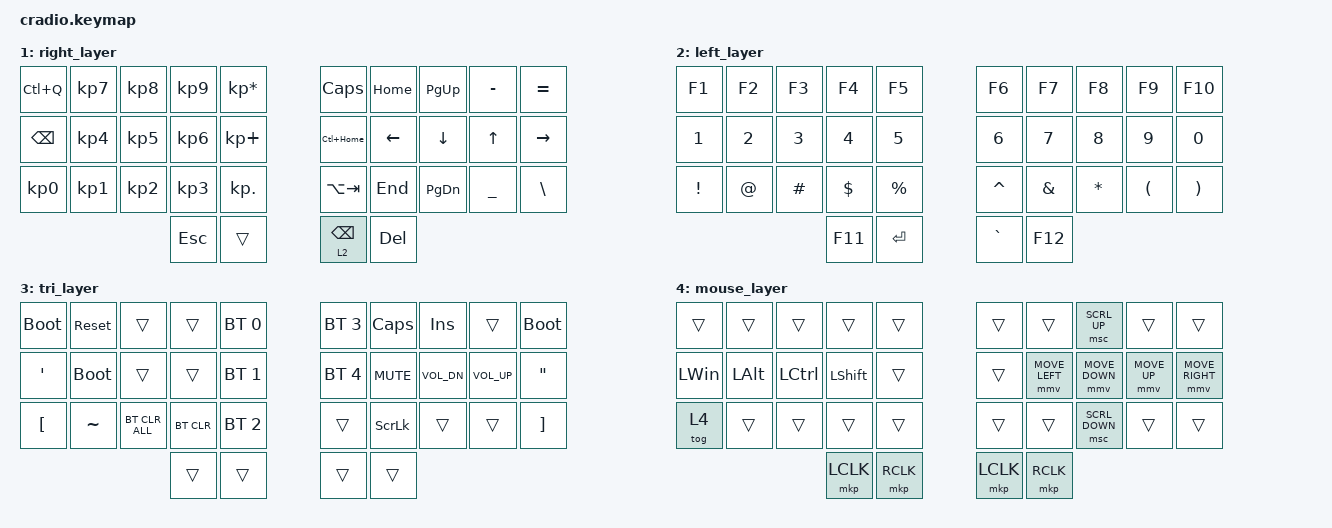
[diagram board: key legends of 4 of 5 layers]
// Copyright (c) 2022 The ZMK Contributors
// SPDX-License-Identifier: MIT

#include <behaviors.dtsi>
#include <dt-bindings/zmk/keys.h>
#include <dt-bindings/zmk/bt.h>

#define ZMK_POINTING_DEFAULT_MOVE_VAL 1500  // default: 600
#define ZMK_POINTING_DEFAULT_SCRL_VAL 20    // default: 10

#include <dt-bindings/zmk/pointing.h>

// Home row mods macro
#define HRML(k1,k2,k3,k4) &ht LGUI k1  &ht LALT k2  &ht LCTRL k3  &ht LSHFT k4
#define HRMR(k1,k2,k3,k4) &ht RSHFT k1  &ht RCTRL k2  &ht RALT k3  &ht RGUI k4

/ {
    behaviors {
        ht: hold_tap {
            label = "hold_tap";
            compatible = "zmk,behavior-hold-tap";
            #binding-cells = <2>;
            flavor = "tap-preferred";
            tapping-term-ms = <220>;
             quick-tap-ms = <150>;
            require-prior-idle-ms = <100>;
            bindings = <&kp>, <&kp>;
        };
    };
 
    combos {
        compatible = "zmk,combos";
        
        combo_esc {
            timeout-ms = <50>;
            key-positions = <0 1>;
            bindings = <&kp ESC>;
        };
        combo_singlequote {
            timeout-ms = <50>;
            key-positions = <18 19>;
            bindings = <&kp SINGLE_QUOTE>;
            layers = <0 1 2 3>;  // Disable in Mouse Layer
        };
        combo_return {
            timeout-ms = <50>;
            key-positions = <17 18>;
            bindings = <&kp ENTER>;
            layers = <0 1 2 3>;  // Disable in Mouse Layer
        };
         combo_doagain {
            timeout-ms = <50>;
            key-positions = <5 6>;
            bindings = <&kp LC(Y)>;
        };
        combo_dash {
            timeout-ms = <50>;
            key-positions = <6 7>;
            bindings = <&kp MINUS>;
        };
        combo_equal {
            timeout-ms = <25>;
            key-positions = <7 8>;
            bindings = <&kp EQUAL>;
            require-prior-idle-ms = <100>;
        };
         combo_backspace {
            timeout-ms = <50>;
            key-positions = <8 9>;
            bindings = <&kp BSPC>;
        };
         combo_bsword {
            timeout-ms = <50>;
            key-positions = <11 12>;
            bindings = <&kp LC(BSPC)>;
        };
          combo_undo {
            timeout-ms = <50>;
            key-positions = <20 21>;
            bindings = <&kp LC(Z)>;
        };
          combo_cut {
            timeout-ms = <50>;
            key-positions = <21 22>;
            bindings = <&kp LC(X)>;
        };
          combo_copy {
            timeout-ms = <50>;
            key-positions = <22 23>;
            bindings = <&kp LC(C)>;
        };
          combo_paste {
            timeout-ms = <50>;
            key-positions = <23 24>;
            bindings = <&kp LC(V)>;
        };
          combo_redo {
            timeout-ms = <50>;
            key-positions = <20 24>;
            bindings = <&kp LC(Y)>;
        };
        combo_togmouse {
            timeout-ms = <50>;
            key-positions = <10 31>;
            bindings = <&tog 4>;
        };
    };

    conditional_layers {
        compatible = "zmk,conditional-layers";
        tri_layer {
            if-layers = <1 2>;
            then-layer = <3>;
        };
    };


    keymap {
        compatible = "zmk,keymap";
        default_layer {
            bindings = <
        //╭──────────┬──────────┬──────────┬──────────┬──────────╮   ╭──────────┬──────────┬──────────┬──────────┬──────────╮
        //│  Q       │  W       │  E       │  R       │  T       │   │  Y       │  U       │  I       │  O       │  P       │
            &kp Q      &kp W      &kp E      &kp R      &kp T          &kp Y      &kp U      &kp I      &kp O      &kp P
        //├──────────┼──────────┼──────────┼──────────┼──────────┤   ├──────────┼──────────┼──────────┼──────────┼──────────┤
        //│  A       │  S       │  D       │  F       │  G       │   │  H       │  J       │  K       │  L       │ ; :      │
            HRML(A,        S,         D,         F)     &kp G          &kp H      HRMR(J,        K,         L,        SEMI)
        //├──────────┼──────────┼──────────┼──────────┼──────────┤   ├──────────┼──────────┼──────────┼──────────┼──────────┤
        //│  Z       │  X       │  C       │  V       │  B       │   │  N       │  M       │ , <      │ . >      │ / ?      │
            &kp Z      &kp X      &kp C      &kp V      &kp B          &kp N      &kp M      &kp COMMA  &kp DOT    &kp FSLH
        //╰──────────┴──────────┴──────────┼──────────┼──────────┤   ├──────────┼──────────┼──────────┴──────────┴──────────╯
                                           &sk LSHIFT   &lt 1 TAB      &lt 2 SPACE  &sk LCTRL 
        //                                 ╰──────────┴──────────╯   ╰──────────┴──────────╯
            >;
        };

//layer 1 arrows keypad backspace Left thumb
        right_layer {
            bindings = <
        //╭──────────┬──────────┬──────────┬──────────┬──────────╮   ╭──────────┬──────────┬──────────┬──────────┬──────────╮
        //│  CTR Q   │  7       │  8       │  9       │     *    │   │  CAPS      │HOME      │ PAGE UP  │   -      │  =       |
          &kp LC(Q)   &kp KP_N7  &kp KP_N8  &kp KP_N9 &kp KP_ASTERISK  &kp CAPS   &kp HOME  &kp PG_UP &kp MINUS  &kp EQUAL
        //├──────────┼──────────┼──────────┼──────────┼──────────┤   ├──────────┼──────────┼──────────┼──────────┼──────────┤
        //│ DELETE   │  4       │  5       │  6       │    +     │   │          │LEFT      │ DOWN     │ UP       │ RIGHT    │ 
            &kp BSPC   &kp KP_N4  &kp KP_N5  &kp KP_N6 &kp KP_PLUS    &kp LC(HOME) &kp LEFT   &kp DOWN    &kp UP     &kp RIGHT   
        //├──────────┼──────────┼──────────┼──────────┼──────────┤   ├──────────┼──────────┼──────────┼──────────┼──────────┤
        //│     0    │  1       │  2       │  3       | KP_DOT   │   │          │  END     │ PAGE DN  |   _      │   \      │  
            &kp KP_N0 &kp KP_N1  &kp KP_N2  &kp KP_N3   &kp KP_DOT   &kp LA(TAB) &kp END   &kp PG_DN  &kp UNDER  &kp BSLH 
        //╰──────────┴──────────┴──────────┼──────────┼──────────┤   ├──────────┼──────────┼──────────┴──────────┴──────────╯
                                              &kp ESC   &trans        &lt 2 BSPC  &kp DEL
        //                                 ╰──────────┴──────────╯   ╰──────────┴──────────╯
            >;
        };

//layer 2 numbers symbols enter right thumb

        left_layer {
            bindings = <
        //╭──────────┬──────────┬──────────┬──────────┬──────────╮   ╭──────────┬──────────┬──────────┬──────────┬──────────╮
        //│     F1   │  F2      │  F3      │  F4      │   F5     │   │  F6      │  F7      │  F8      │  F9      │  F10     │
            &kp F1      &kp F2    &kp F3     &kp F4     &kp F5         &kp F6     &kp F7     &kp F8     &kp F9     &kp F10        
        //├──────────┼──────────┼──────────┼──────────┼──────────┤   ├──────────┼──────────┼──────────┼──────────┼──────────┤
        //│  1       │  2       │  3       │  4       │  5       │   │  6       │  7       │  8       │  9       │  0       │
            &kp N1     &kp N2     &kp N3     &kp N4     &kp N5         &kp N6     &kp N7     &kp N8     &kp N9     &kp N0   
        //├──────────┼──────────┼──────────┼──────────┼──────────┤   ├──────────┼──────────┼──────────┼──────────┼──────────┤
        //│  !       │  @       │  #       │  $       │  %       │   │   ^      | &        │   *      |  (       │  )       │  
            &kp EXCL   &kp AT     &kp HASH   &kp DLLR   &kp PRCNT      &kp CARET  &kp AMPS  &kp ASTRK  &kp LPAR   &kp RPAR   
        //╰──────────┴──────────┴──────────┼──────────┼──────────┤   ├──────────┼──────────┼──────────┴──────────┴──────────╯
                                            &kp F11   &kp ENTER      &kp GRAVE  &kp F12  
        //                                 ╰──────────┴──────────╯   ╰──────────┴──────────╯
            >;
        };

        tri_layer {
            bindings = <
        //╭──────────┬──────────┬──────────┬──────────┬──────────╮   ╭──────────┬──────────┬──────────┬──────────┬──────────╮
        //│BOOTLOADER│   RESET  │          │          │PROFILE 0 │   │PROFILE 3 │          │          │          │     │
           &bootloader  &sys_reset  &trans     &trans  &bt BT_SEL 0   &bt BT_SEL 3 &kp CAPS   &kp INS    &trans    &bootloader 
        //├──────────┼──────────┼──────────┼──────────┼──────────┤   ├──────────┼──────────┼──────────┼──────────┼──────────┤
        //│ │ SQT    |BOOTLOADER│          │          │PROFILE 1 │   │Profile 4 │          │          │          |  DQT     |
          &kp SINGLE_QUOTE &bootloader &trans &trans &bt BT_SEL 1  &bt BT_SEL 4   &kp C_MUTE &kp C_VOL_DN &kp C_VOL_UP &kp DQT
        //├──────────┼──────────┼──────────┼──────────┼──────────┤   ├──────────┼──────────┼──────────┼──────────┼──────────┤
        //│          │          │BTCLEARALL│ CLEAR BT │PROFILE 2 │   │          │          │          │          │          │
            &kp LBKT  &kp TILDE  &bt BT_CLR_ALL &bt BT_CLR  &bt BT_SEL 2 &trans  &kp SLCK    &trans     &trans     &kp RBKT
        //╰──────────┴──────────┴──────────┼──────────┼──────────┤   ├──────────┼──────────┼──────────┴──────────┴──────────╯
                                             &trans     &trans         &trans     &trans
        //                                 ╰──────────┴──────────╯   ╰──────────┴──────────╯
            >;
        };

         mouse_layer {
            bindings = <
        //╭──────────┬──────────┬──────────┬──────────┬──────────╮   ╭──────────┬──────────┬──────────┬──────────┬──────────╮
        //│          │          │          │          │          │   │          │          │          │          │          │
            &trans     &trans     &trans     &trans     &trans         &trans     &trans     &msc SCRL_UP     &trans     &trans
        //├──────────┼──────────┼──────────┼──────────┼──────────┤   ├──────────┼──────────┼──────────┼──────────┼──────────┤
        //│          │          │          │          │          │   │          │ M_LEFT   │ M_DOWN   │ M_UP     │ M_RIGHT  │
            &kp LWIN  &kp LALT    &kp LCTRL &kp LSHFT   &trans          &trans &mmv MOVE_LEFT &mmv MOVE_DOWN &mmv MOVE_UP &mmv MOVE_RIGHT
        //├──────────┼──────────┼──────────┼──────────┼──────────┤   ├──────────┼──────────┼──────────┼──────────┼──────────┤
        //│          │          │          │          │          │   │          │          │          │          │          │
            &tog 4     &trans    &trans      &trans    &trans         &trans     &trans  &msc SCRL_DOWN    &trans     &trans
        //╰──────────┴──────────┴──────────┼──────────┼──────────┤   ├──────────┼──────────┼──────────┴──────────┴──────────╯
                                            &mkp LCLK   &mkp RCLK      &mkp LCLK  &mkp RCLK
        //                                 ╰──────────┴──────────╯   ╰──────────┴──────────╯
            >;
        };
    };
};
